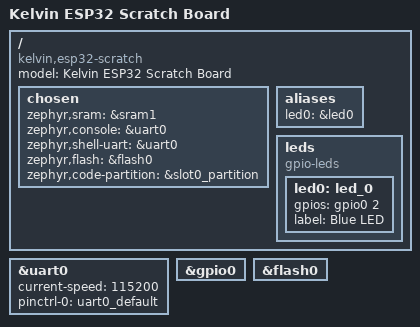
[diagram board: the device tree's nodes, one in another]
/dts-v1/;

#include <espressif/esp32/esp32_wroom_32ue_n4.dtsi>
#include "kelvin_esp32_scratch-pinctrl.dtsi"
#include <espressif/partitions_0x1000_amp.dtsi>

/ {
    model = "Kelvin ESP32 Scratch Board";
    compatible = "kelvin,esp32-scratch";

    chosen {
        zephyr,sram = &sram1;
        zephyr,console = &uart0;
        zephyr,shell-uart = &uart0;
        zephyr,flash = &flash0;
        zephyr,code-partition = &slot0_partition;
    };

    aliases {
        led0 = &led0;
    };

    leds {
        compatible = "gpio-leds";

        led0: led_0 {
            gpios = <&gpio0 2 GPIO_ACTIVE_HIGH>;
            label = "Blue LED";
        };
    };
};

&uart0 {
    status = "okay";
    current-speed = <115200>;
    pinctrl-0 = <&uart0_default>;
    pinctrl-names = "default";
};

&gpio0 {
    status = "okay";
};

&flash0 {
    status = "okay";
};
